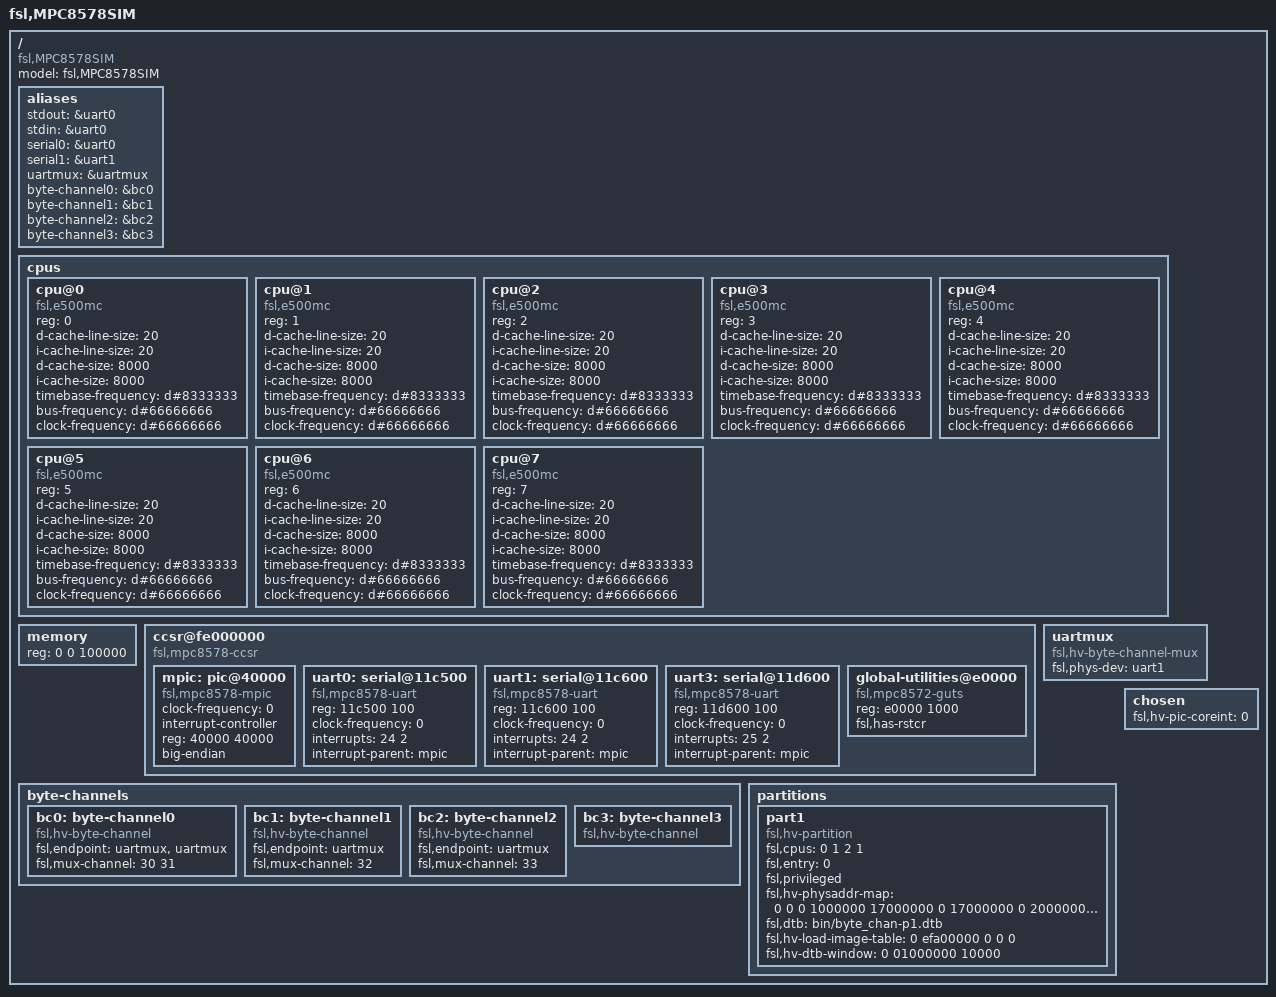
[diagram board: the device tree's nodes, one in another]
/ {
	model = "fsl,MPC8578SIM";
	compatible = "fsl,MPC8578SIM";
	#address-cells = <2>;
	#size-cells = <1>;

	aliases {
		stdout = &uart0;
		stdin = &uart0;
		serial0 = &uart0;
		serial1 = &uart1;
		uartmux = &uartmux;
		byte-channel0 = &bc0;
		byte-channel1 = &bc1;
		byte-channel2 = &bc2;
		byte-channel3 = &bc3;
	};

	cpus {
		#address-cells = <1>;
		#size-cells = <0>;

		cpu@0 {
			device_type = "cpu";
			compatible = "fsl,e500mc", "fsl,e500";
			reg = <0>;
			d-cache-line-size = <20>;
			i-cache-line-size = <20>;
			d-cache-size = <8000>;
			i-cache-size = <8000>;
			timebase-frequency = <d#8333333>;
			bus-frequency = <d#66666666>;
			clock-frequency = <d#66666666>;
		};

		cpu@1 {
			device_type = "cpu";
			compatible = "fsl,e500mc", "fsl,e500";
			reg = <1>;
			d-cache-line-size = <20>;
			i-cache-line-size = <20>;
			d-cache-size = <8000>;
			i-cache-size = <8000>;
			timebase-frequency = <d#8333333>;
			bus-frequency = <d#66666666>;
			clock-frequency = <d#66666666>;
		};

		cpu@2 {
			device_type = "cpu";
			compatible = "fsl,e500mc", "fsl,e500";
			reg = <2>;
			d-cache-line-size = <20>;
			i-cache-line-size = <20>;
			d-cache-size = <8000>;
			i-cache-size = <8000>;
			timebase-frequency = <d#8333333>;
			bus-frequency = <d#66666666>;
			clock-frequency = <d#66666666>;
		};

		cpu@3 {
			device_type = "cpu";
			compatible = "fsl,e500mc", "fsl,e500";
			reg = <3>;
			d-cache-line-size = <20>;
			i-cache-line-size = <20>;
			d-cache-size = <8000>;
			i-cache-size = <8000>;
			timebase-frequency = <d#8333333>;
			bus-frequency = <d#66666666>;
			clock-frequency = <d#66666666>;
		};

		cpu@4 {
			device_type = "cpu";
			compatible = "fsl,e500mc", "fsl,e500";
			reg = <4>;
			d-cache-line-size = <20>;
			i-cache-line-size = <20>;
			d-cache-size = <8000>;
			i-cache-size = <8000>;
			timebase-frequency = <d#8333333>;
			bus-frequency = <d#66666666>;
			clock-frequency = <d#66666666>;
		};

		cpu@5 {
			device_type = "cpu";
			compatible = "fsl,e500mc", "fsl,e500";
			reg = <5>;
			d-cache-line-size = <20>;
			i-cache-line-size = <20>;
			d-cache-size = <8000>;
			i-cache-size = <8000>;
			timebase-frequency = <d#8333333>;
			bus-frequency = <d#66666666>;
			clock-frequency = <d#66666666>;
		};

		cpu@6 {
			device_type = "cpu";
			compatible = "fsl,e500mc", "fsl,e500";
			reg = <6>;
			d-cache-line-size = <20>;
			i-cache-line-size = <20>;
			d-cache-size = <8000>;
			i-cache-size = <8000>;
			timebase-frequency = <d#8333333>;
			bus-frequency = <d#66666666>;
			clock-frequency = <d#66666666>;
		};

		cpu@7 {
			device_type = "cpu";
			compatible = "fsl,e500mc", "fsl,e500";
			reg = <7>;
			d-cache-line-size = <20>;
			i-cache-line-size = <20>;
			d-cache-size = <8000>;
			i-cache-size = <8000>;
			timebase-frequency = <d#8333333>;
			bus-frequency = <d#66666666>;
			clock-frequency = <d#66666666>;
		};
	};

	memory {
		reg = <0 0 100000>;
		device_type = "memory";
	};

	ccsr@fe000000 {
		#address-cells = <1>;
		#size-cells = <1>;
		compatible = "fsl,mpc8578-ccsr", "simple-bus";
		ranges = <0 0 fe000000 400000>;

		mpic: pic@40000 {
			clock-frequency = <0>;
			interrupt-controller;
			#address-cells = <0>;
			#interrupt-cells = <2>;
			reg = <40000 40000>;
			compatible = "fsl,mpc8578-mpic", "fsl,mpic",
			             "chrp,open-pic";
			device_type = "open-pic";
			big-endian;
		};

		uart0: serial@11c500 {
			device_type = "serial";
			compatible = "fsl,mpc8578-uart", "fsl,ns16550", "ns16550";
			reg = <11c500 100>;
			clock-frequency = <0>;
			interrupts = <24 2>;
			interrupt-parent = <&mpic>;
		};

		uart1: serial@11c600 {
			device_type = "serial";
			compatible = "fsl,mpc8578-uart", "fsl,ns16550", "ns16550";
			reg = <11c600 100>;
			clock-frequency = <0>;
			interrupts = <24 2>;
			interrupt-parent = <&mpic>;
		};

		uart3: serial@11d600 {
			device_type = "serial";
			compatible = "fsl,mpc8578-uart", "fsl,ns16550", "ns16550";
			reg = <11d600 100>;
			clock-frequency = <0>;
			interrupts = <25 2>;
			interrupt-parent = <&mpic>;
		};

		global-utilities@e0000 {	//global utilities block
			compatible = "fsl,mpc8572-guts";
			reg = <e0000 1000>;
			fsl,has-rstcr;
		};
	};

	uartmux: uartmux {
		compatible = "fsl,hv-byte-channel-mux";
		fsl,phys-dev = <&uart1>;
	};

	byte-channels {
                /* bc0 here is a weird case for testing purposes.
		 * It sets up a loopback in the mux, so that
		 * data coming in channel 0 goes out channel 1.
		 * bc0 is _not_ usable by a guest.
		 */
		bc0: byte-channel0 {
			compatible = "fsl,hv-byte-channel";
			fsl,endpoint = <&uartmux &uartmux>;
			fsl,mux-channel = <30 31>;
		};

		bc1: byte-channel1 {
			compatible = "fsl,hv-byte-channel";
			fsl,endpoint = <&uartmux>;
			fsl,mux-channel = <32>;
		};

		bc2: byte-channel2 {
			compatible = "fsl,hv-byte-channel";
			fsl,endpoint = <&uartmux>;
			fsl,mux-channel = <33>;
		};
		bc3: byte-channel3 {
			compatible = "fsl,hv-byte-channel";
		};
	};

	partitions {
		part1 {
			compatible = "fsl,hv-partition";
			fsl,cpus = <0 1 2 1>;
			fsl,entry = <0>;
			fsl,privileged;
			fsl,hv-physaddr-map = <0 0 0 1000000 17000000
			                 0 17000000 0 20000000 1000000>;
			fsl,dtb = /incbin/("bin/byte_chan-p1.dtb");
			fsl,hv-load-image-table = <0 efa00000 0 0 0>;
			fsl,hv-dtb-window = <0 01000000 10000>;
		};
	};

	chosen {
		fsl,hv-pic-coreint = <0>;
	};
};
